# RL6842_IP_SVD register map
Vendor: Realtek
Registers are 32-bit, read-write, reset 0x0 unless marked. A register's access mark holds for its fields unless they carry their own. Offsets are from the block's base; [hi:lo] are bit positions; {n}, {i} and the like mark numbered series.

## IPC0_REG
Base 0x41020000
Same registers: IPC1_REG 0x41020080, IPC2_REG 0x41020100
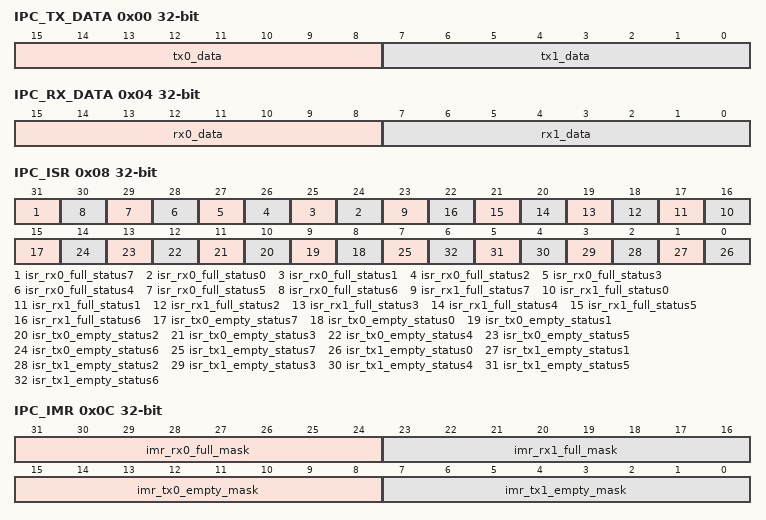
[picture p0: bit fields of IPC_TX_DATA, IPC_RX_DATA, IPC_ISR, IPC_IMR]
0x00 IPC_TX_DATA — Tx Register
  [15:8] tx0_data — After preparing descriptor, data and corresponding memory, 1: Writing 1 to the Tx data register (TX0_DATA) channel x bit, and the data will be mapped to the CPU0's RX data register (RX0_DATA) channel x bit. And the corresponding Rx full status bit in REG_ISR_CPU0 will be set. 0: Writing 0 has no effect. If the corresponding Rx full status bit in REG_ISR_CPU0 (eg. ISR_RX0_FULL_STATUS6) is cleared, the corresponding bit in tx0_data will be cleaned automatically.
  [7:0] tx1_data — After preparing descriptor, data and corresponding memory, 1: Writing 1 to the Tx data register (TX1_DATA) channel x bit, and the data will be mapped to the CPU1's Rx data register (RX1_DATA) channel x bit. And the corresponding Rx full status bit in REG_ISR_CPU1 will be set. 0: Writing 0 has no effect. If the corresponding Rx full status bit in REG_ISR_CPU1 (eg. ISR_RX1_FULL_STATUS6) is cleared, the corresponding bit in tx_data_ln will be cleaned automatically.
0x04 IPC_RX_DATA ro — Rx Register
  [15:8] rx0_data — Rx data automatically maps data from TX0_DATA of CPU0
  [7:0] rx1_data — Rx data automatically maps data from TX1_DATA of CPU1
0x08 IPC_ISR ro — Interrupt Status Register
  [31] isr_rx0_full_status7 — Rx channel 7 full interrupt status of CPU3. The corresponding Rx full status bit will be set by CPU0's Tx data register (tx0_data) channel 7. It will be cleared by software writing 1.
  [n+24] isr_rx0_full_status{n} (n=0..6) — Refer to the description of the ISR_RX0_FULL_STATUS7.
  [23] isr_rx1_full_status7 — Rx channel 7 full interrupt status of CPU3. The corresponding Rx full status bit will be set by CPU1's Tx data register (tx1_data) channel 7. It will be cleared by software writing 1.
  [n+16] isr_rx1_full_status{n} (n=0..6) — Refer to the description of the ISR_RX1_FULL_STATUS7.
  [15] isr_tx0_empty_status7 — Tx channel 7 empty interrupt status of CPU3 transmit to CPU0. If the corresponding Rx full status bit in REG_ISR_CPU0 (eg. ISR_RX0_FULL_STATUS7) is cleared, the corresponding Tx empty status bit will be set automatically. It will be cleared by software writing 1.
  [n+8] isr_tx0_empty_status{n} (n=0..6) — Refer to the description of the ISR_TX0_EMPTY_STATUS7.
  [7] isr_tx1_empty_status7 — Tx channel 7 empty interrupt status of CPU3 transmit to CPU1. If the corresponding Rx full status bit in REG_ISR_CPU1 (eg. ISR_RX1_FULL_STATUS7) is cleared, the corresponding Tx empty status bit will be set automatically. It will be cleared by software writing 1.
  [n] isr_tx1_empty_status{n} (n=0..6) — Refer to the description of the ISR_TX1_EMPTY_STATUS7.
0x0C IPC_IMR — Interrupt Mask Register
  [31:24] imr_rx0_full_mask — 0: Mask Rx Channel x full interrupt of CPU3 received from CPU0 1: Unmask Rx Channel x full interrupt of CPU3 received from CPU0
  [23:16] imr_rx1_full_mask — 0: Mask Rx Channel x full interrupt of CPU3 received from CPU1 1: Unmask Rx Channel x full interrupt of CPU3 received from CPU1
  [15:8] imr_tx0_empty_mask — 0: Mask Tx Channel x empty interrupt of CPU3 transmit to CPU0 1: Unmask Tx Channel x empty interrupt of CPU3 transmit to CPU0
  [7:0] imr_tx1_empty_mask — 0: Mask Tx Channel x empty interrupt of CPU3 transmit to CPU1 1: Unmask Tx Channel x empty interrupt of CPU3 transmit to CPU1
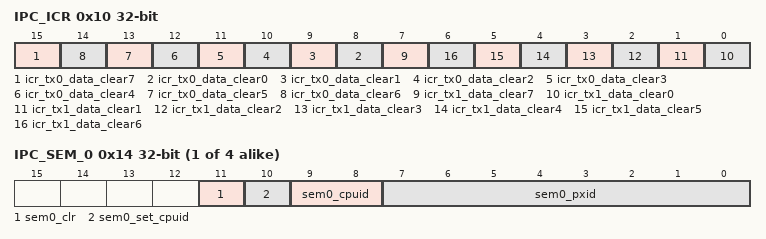
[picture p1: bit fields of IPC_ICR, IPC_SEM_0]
0x10 IPC_ICR ro — Clear Tx Register
  [15] icr_tx0_data_clear7 — 0: Writing 0 has no effect. 1: Clear the Tx data register (TX0_DATA) channel 7 bit.
  [n+8] icr_tx0_data_clear{n} (n=0..6) — Refer to the description of the ICR_TX0_DATA_CLEAR7.
  [7] icr_tx1_data_clear7 — 0: Writing 0 has no effect. 1: Clear the Tx data register (TX1_DATA) channel 7 bit.
  [n] icr_tx1_data_clear{n} (n=0..6) — Refer to the description of the ICR_TX1_DATA_CLEAR7.
{0x14+4i} IPC_SEM_{i} access per field (i=0..3)
  [11] sem{i}_clr wo — The bit can clear 'CPUID ' & 'PXID' when owner CPU writes 1.
  [10] sem{i}_set_cpuid wo — The bit can set CPUID, It must be written at the same time as SEM{i}_PXID.
  [9:8] sem{i}_cpuid ro — 'CPUID' bit is a read-only bit. 00: Currently semaphore can be occupied by CPU. When writing PXID, hardware sets CPUID. 01: Currently semaphore is occupied by KR4. 10: Currently semaphore is occupied by KM4. 11: Currently semaphore is occupied by HiFI5.
  [7:0] sem{i}_pxid rw — CPUID_PXID, which is used to indicate who owns this semaphore when the CPUID is the same.
0x24 IPC_DUMMY — Dummy Register
  [15:0] dummy
